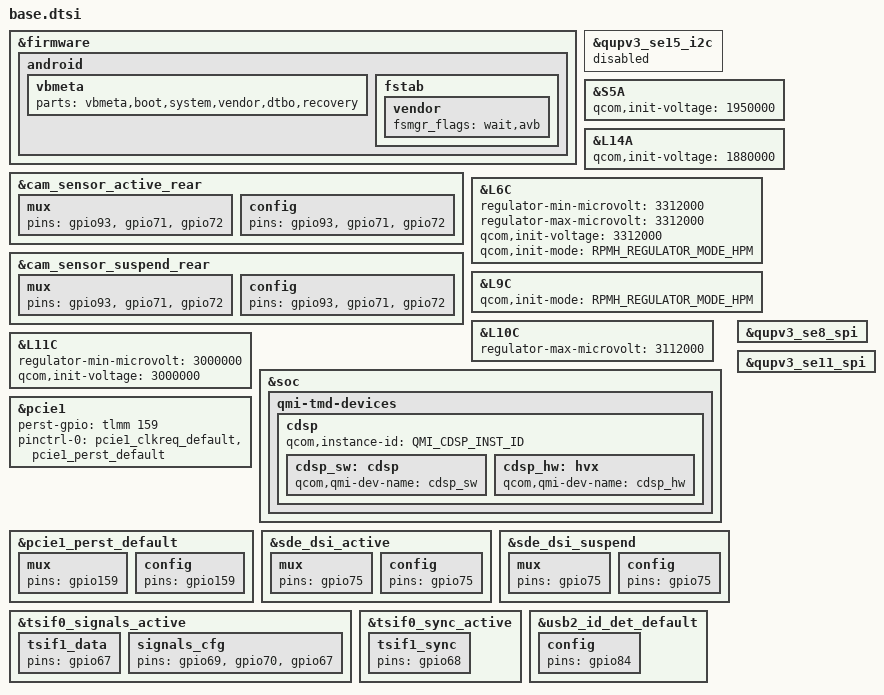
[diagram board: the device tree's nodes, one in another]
#include "audio.dtsi"
#include "others.dtsi"
#include "display.dtsi"
#include "camera.dtsi"
#include "tp.dtsi"
#include "haptic.dtsi"

#include "sensors.dtsi"
#include "leds.dtsi"
#include "aw22xxx.dtsi"
#include "neo-power.dtsi"
#include "nfc.dtsi"
#include "usb.dtsi"
#include "finger.dtsi"

&firmware {
	android {
		vbmeta {
			parts = "vbmeta,boot,system,vendor,dtbo,recovery";
		};

		fstab {
			vendor {
				fsmgr_flags = "wait,avb";
			};
		};
	};
};

&qupv3_se15_i2c {
	status = "disabled";
	/delete-node/ nq@64;
};

&cam_sensor_active_rear {
	mux {
		pins = "gpio93", "gpio71", "gpio72";
	};

	config {
		pins = "gpio93", "gpio71", "gpio72";
	};
};

&cam_sensor_suspend_rear {
	mux {
		pins = "gpio93", "gpio71", "gpio72";
	};

	config {
		pins = "gpio93", "gpio71", "gpio72";
	};
};

&S5A {
	qcom,init-voltage = <1950000>;
};

&L14A {
	qcom,init-voltage = <1880000>;
};

&L6C {
	regulator-min-microvolt = <3312000>; //1800000
	regulator-max-microvolt = <3312000>;
	qcom,init-voltage = <3312000>; //1800000
	qcom,init-mode = <RPMH_REGULATOR_MODE_HPM>;
};

&L9C {
	qcom,init-mode = <RPMH_REGULATOR_MODE_HPM>;
};

&L10C {
	regulator-max-microvolt = <3112000>;
};

&L11C {
	regulator-min-microvolt = <3000000>;
	qcom,init-voltage = <3000000>;
};

&soc {
	qmi-tmd-devices {
		cdsp {
			qcom,instance-id = <QMI_CDSP_INST_ID>;

			cdsp_sw: cdsp {
				qcom,qmi-dev-name = "cdsp_sw";
				#cooling-cells = <2>;
			};

			cdsp_hw: hvx {
				qcom,qmi-dev-name = "cdsp_hw";
				#cooling-cells = <2>;
			};
		};
	};
};

&pcie1 {
	/delete-property/ wake-gpio;

	perst-gpio = <&tlmm 159 0>;
	pinctrl-0 = <&pcie1_clkreq_default
			&pcie1_perst_default>;
};

&pcie1_perst_default {
	mux {
		pins = "gpio159";
	};

	config {
		pins = "gpio159";
	};
};

&sde_dsi_active {
	mux {
		pins = "gpio75";
	};

	config {
		pins = "gpio75";
	};
};

&sde_dsi_suspend {
	mux {
		pins = "gpio75";
	};

	config {
		pins = "gpio75";
	};
};

&tsif0_signals_active {
	tsif1_data {
		pins = "gpio67"; /* TSIF0 DATA */
	};

	signals_cfg {
		pins = "gpio69", "gpio70","gpio67";
	};
};

&tsif0_sync_active {
	tsif1_sync {
		pins = "gpio68"; /* TSIF0 SYNC */
	};
};

&usb2_id_det_default {
	config {
		pins = "gpio84";
	};
};

&qupv3_se8_spi {
	/delete-property/ pinctrl-0;
	/delete-property/ pinctrl-1;
};

&qupv3_se11_spi {
	/delete-property/ pinctrl-0;
	/delete-property/ pinctrl-1;
};
